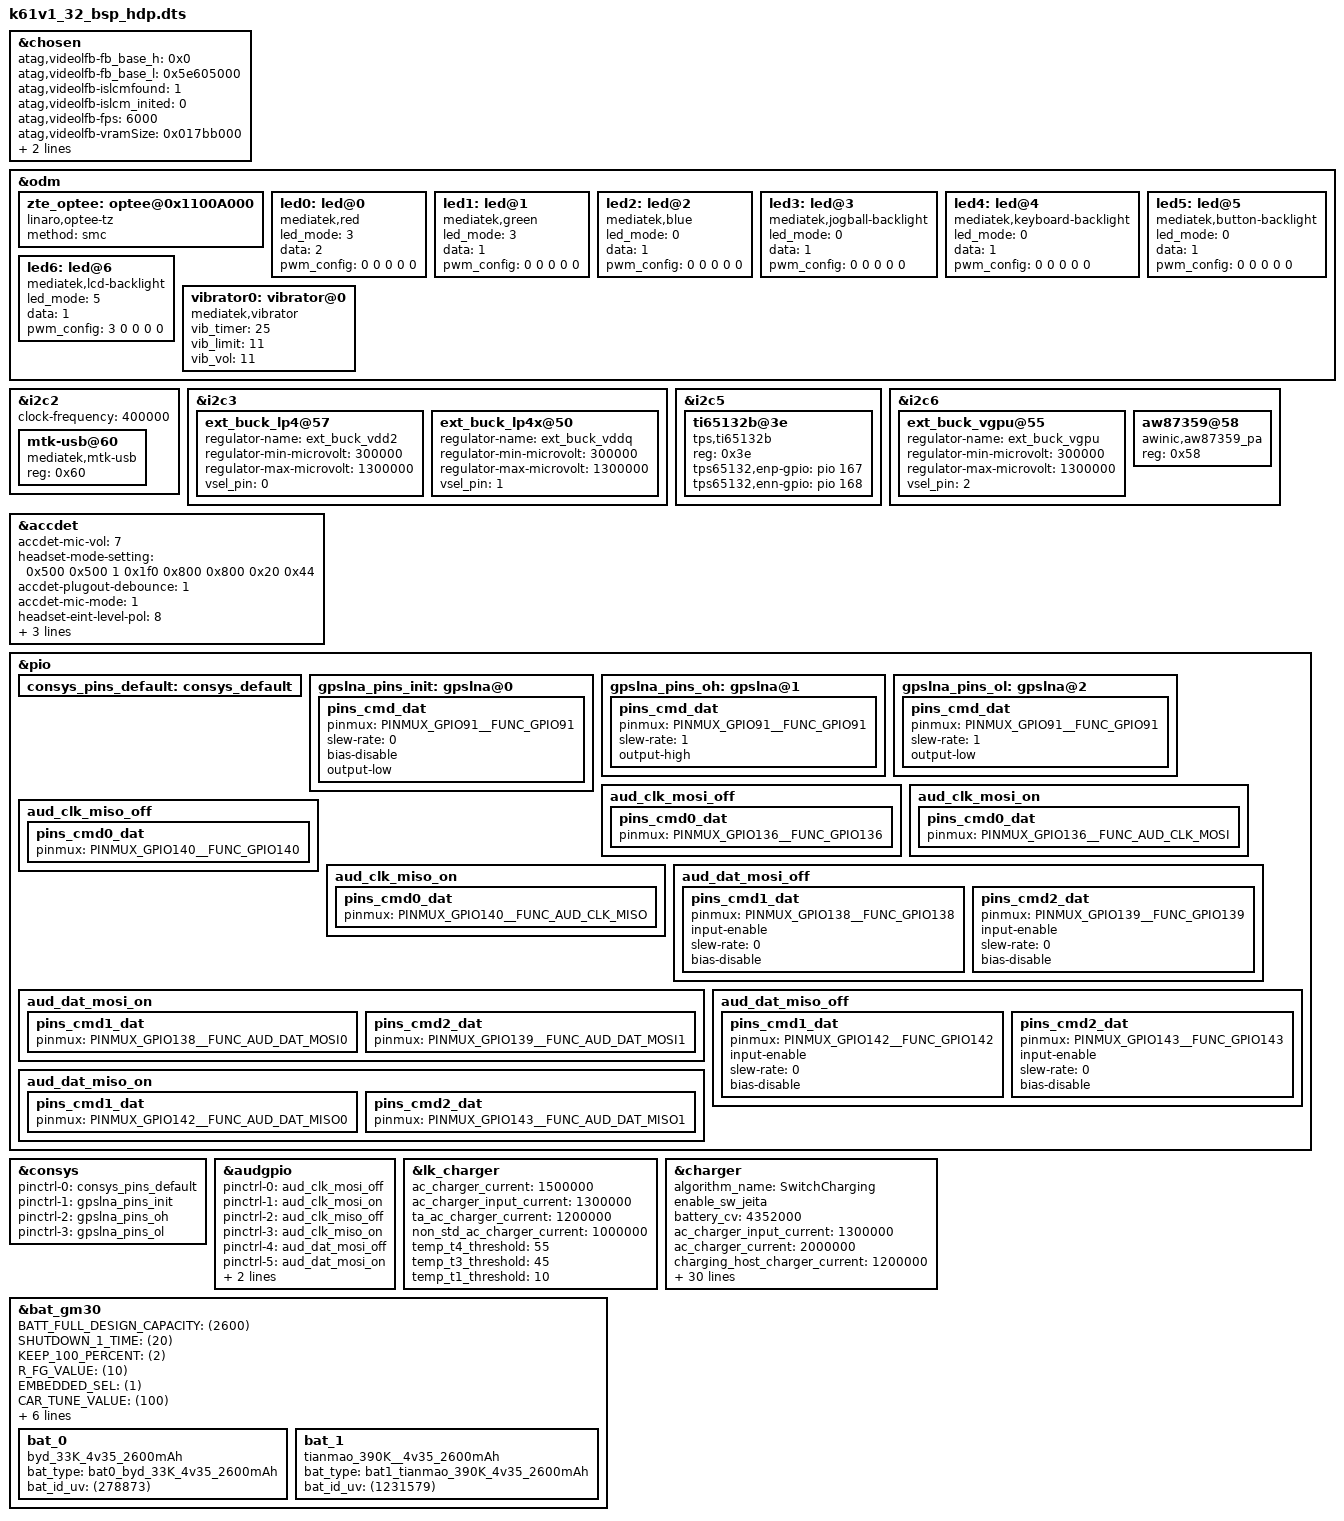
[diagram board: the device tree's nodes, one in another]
/*
 * Copyright (C) 2019 MediaTek Inc.
 *
 * This program is free software; you can redistribute it and/or modify
 * it under the terms of the GNU General Public License version 2 as
 * published by the Free Software Foundation.
 *
 * This program is distributed in the hope that it will be useful,
 * but WITHOUT ANY WARRANTY; without even the implied warranty of
 * MERCHANTABILITY or FITNESS FOR A PARTICULAR PURPOSE.
 * See http://www.gnu.org/licenses/gpl-2.0.html for more details.
 */

#include <dt-bindings/interrupt-controller/arm-gic.h>
#include <dt-bindings/interrupt-controller/irq.h>
#include <dt-bindings/pinctrl/mt6761-pinfunc.h>
#include <dt-bindings/mmc/mt6761-msdc.h>
#include <dt-bindings/clock/mt6761-clk.h>

/dts-v1/;
/plugin/;

#include "touchscreen_mango.dtsi"

/* chosen */
&chosen {

	/* fpga may has no lk, we need to specify display info here */
	/* fb buffer is reserved using this dts by memory node above */
	atag,videolfb-fb_base_h = <0x0>;
	atag,videolfb-fb_base_l = <0x5e605000>;
	atag,videolfb-islcmfound = <1>;
	/* because no lk, so lcm is not inited */
	atag,videolfb-islcm_inited = <0>;
	atag,videolfb-fps= <6000>;
	atag,videolfb-vramSize= <0x017bb000>;
	atag,videolfb-lcmname= "nt35521_hd_dsi_vdo_truly_rt5081_drv";
};

&odm {
	zte_optee: optee@0x1100A000 {
		compatible = "linaro,optee-tz";
		method = "smc";
	};
	led0:led@0 {
		compatible = "mediatek,red";
		led_mode = <3>;
		data = <2>;
		pwm_config = <0 0 0 0 0>;
	};
	led1:led@1 {
		compatible = "mediatek,green";
		led_mode = <3>;
		data = <1>;
		pwm_config = <0 0 0 0 0>;
	};
	led2:led@2 {
		compatible = "mediatek,blue";
		led_mode = <0>;
		data = <1>;
		pwm_config = <0 0 0 0 0>;
	};
	led3:led@3 {
		compatible = "mediatek,jogball-backlight";
		led_mode = <0>;
		data = <1>;
		pwm_config = <0 0 0 0 0>;
	};
	led4:led@4 {
		compatible = "mediatek,keyboard-backlight";
		led_mode = <0>;
		data = <1>;
		pwm_config = <0 0 0 0 0>;
	};
	led5:led@5 {
		compatible = "mediatek,button-backlight";
		led_mode = <0>;
		data = <1>;
		pwm_config = <0 0 0 0 0>;
	};
	led6:led@6 {
		compatible = "mediatek,lcd-backlight";
		led_mode = <5>;
		data = <1>;
		pwm_config = <3 0 0 0 0>;
	};
	vibrator0:vibrator@0 {
		compatible = "mediatek,vibrator";
		vib_timer = <25>;
		vib_limit = <11>;
		vib_vol= <11>;
	};
};

&i2c2 {
	#address-cells = <1>;
	#size-cells = <0>;
	clock-frequency = <400000>;

	mtk-usb@60 {
		compatible = "mediatek,mtk-usb";
		reg = <0x60>;
		status = "okay";
	};
};

&i2c3 {
	ext_buck_lp4@57 {
		regulator-name ="ext_buck_vdd2";
		regulator-min-microvolt = <300000>;
		regulator-max-microvolt = <1300000>;
		vsel_pin = <0>;
	};

	ext_buck_lp4x@50 {
		regulator-name ="ext_buck_vddq";
		regulator-min-microvolt = <300000>;
		regulator-max-microvolt = <1300000>;
		vsel_pin = <1>;
	};
};
&i2c5 {
       ti65132b@3e {
               compatible = "tps,ti65132b";
               reg = <0x3e>;
               tps65132,enp-gpio = <&pio 167 0x00>;
               tps65132,enn-gpio = <&pio 168 0x00>;
       };
};

&i2c6 {
	ext_buck_vgpu@55 {
		regulator-name ="ext_buck_vgpu";
		regulator-min-microvolt = <300000>;
		regulator-max-microvolt = <1300000>;
		vsel_pin = <2>;
	};
};

&accdet {
	accdet-mic-vol = <7>;
	headset-mode-setting = <0x500 0x500 1 0x1f0 0x800 0x800 0x20 0x44>;
	accdet-plugout-debounce = <1>;
	accdet-mic-mode = <1>;
	headset-eint-level-pol = <8>;
	headset-three-key-threshold = <0 80 220 400>;
	headset-three-key-threshold-CDD = <0 121 192 600>;
	headset-four-key-threshold = <0 58 121 192 400>;
	status = "okay";
};

/* CONSYS GPIO standardization */
&pio {
	consys_pins_default: consys_default {
	};
	gpslna_pins_init: gpslna@0 {
		pins_cmd_dat {
			pinmux = <PINMUX_GPIO91__FUNC_GPIO91>;
			slew-rate = <0>;
			bias-disable;
			output-low;
		};
	};
	gpslna_pins_oh: gpslna@1 {
		pins_cmd_dat {
			pinmux = <PINMUX_GPIO91__FUNC_GPIO91>;
			slew-rate = <1>;
			output-high;
		};
	};
	gpslna_pins_ol: gpslna@2 {
		pins_cmd_dat {
			pinmux = <PINMUX_GPIO91__FUNC_GPIO91>;
			slew-rate = <1>;
			output-low;
		};
	};
};
&consys {
	pinctrl-names = "default", "gps_lna_state_init",
		"gps_lna_state_oh", "gps_lna_state_ol";
	pinctrl-0 = <&consys_pins_default>;
	pinctrl-1 = <&gpslna_pins_init>;
	pinctrl-2 = <&gpslna_pins_oh>;
	pinctrl-3 = <&gpslna_pins_ol>;
	status = "okay";
};
/* CONSYS end */

/* AWINIC AW87359 Smart PA */
&i2c6 {
    aw87359@58 {
        compatible = "awinic,aw87359_pa";
        reg = <0x58>;
        status = "okay";
    };
};
/* AWINIC AW87359 Smart PA End */

/* AUDIO GPIO standardization */
&audgpio {
	pinctrl-names = "aud_clk_mosi_off",
			"aud_clk_mosi_on",
			"aud_clk_miso_off",
			"aud_clk_miso_on",
			"aud_dat_mosi_off",
			"aud_dat_mosi_on",
			"aud_dat_miso_off",
			"aud_dat_miso_on";
	pinctrl-0 = <&aud_clk_mosi_off>;
	pinctrl-1 = <&aud_clk_mosi_on>;
	pinctrl-2 = <&aud_clk_miso_off>;
	pinctrl-3 = <&aud_clk_miso_on>;
	pinctrl-4 = <&aud_dat_mosi_off>;
	pinctrl-5 = <&aud_dat_mosi_on>;
	pinctrl-6 = <&aud_dat_miso_off>;
	pinctrl-7 = <&aud_dat_miso_on>;
	status = "okay";
};

&pio {
	aud_clk_mosi_off: aud_clk_mosi_off {
		pins_cmd0_dat {
			pinmux = <PINMUX_GPIO136__FUNC_GPIO136>;
		};
	};

	aud_clk_mosi_on: aud_clk_mosi_on {
		pins_cmd0_dat {
			pinmux = <PINMUX_GPIO136__FUNC_AUD_CLK_MOSI>;
		};
	};

	aud_clk_miso_off: aud_clk_miso_off {
		pins_cmd0_dat {
			pinmux = <PINMUX_GPIO140__FUNC_GPIO140>;
		};
	};

	aud_clk_miso_on: aud_clk_miso_on {
		pins_cmd0_dat {
			pinmux = <PINMUX_GPIO140__FUNC_AUD_CLK_MISO>;
		};
	};

	aud_dat_mosi_off: aud_dat_mosi_off {
		pins_cmd1_dat {
			pinmux = <PINMUX_GPIO138__FUNC_GPIO138>;
			input-enable;
			slew-rate = <0>;
			bias-disable;
		};
		pins_cmd2_dat {
			pinmux = <PINMUX_GPIO139__FUNC_GPIO139>;
			input-enable;
			slew-rate = <0>;
			bias-disable;
		};
	};

	aud_dat_mosi_on: aud_dat_mosi_on {
		pins_cmd1_dat {
			pinmux = <PINMUX_GPIO138__FUNC_AUD_DAT_MOSI0>;
		};
		pins_cmd2_dat {
			pinmux = <PINMUX_GPIO139__FUNC_AUD_DAT_MOSI1>;
		};
	};

	aud_dat_miso_off: aud_dat_miso_off {
		pins_cmd1_dat {
			pinmux = <PINMUX_GPIO142__FUNC_GPIO142>;
			input-enable;
			slew-rate = <0>;
			bias-disable;
		};
		pins_cmd2_dat {
			pinmux = <PINMUX_GPIO143__FUNC_GPIO143>;
			input-enable;
			slew-rate = <0>;
			bias-disable;
		};
	};

	aud_dat_miso_on: aud_dat_miso_on {
		pins_cmd1_dat {
			pinmux = <PINMUX_GPIO142__FUNC_AUD_DAT_MISO0>;
		};
		pins_cmd2_dat {
			pinmux = <PINMUX_GPIO143__FUNC_AUD_DAT_MISO1>;
		};
	};
};
/* AUDIO end */


&lk_charger {
	ac_charger_current = <1500000>;
	ac_charger_input_current = <1300000>;
	ta_ac_charger_current = <1200000>;
	non_std_ac_charger_current = <1000000>;

	/* battery temperature protection */
	temp_t4_threshold = <55>;
	temp_t3_threshold = <45>;
	temp_t1_threshold = <10>;
};

&charger {
	algorithm_name = "SwitchCharging";
	enable_sw_jeita;
	battery_cv = <4352000>;
	ac_charger_input_current = <1300000>;
	ac_charger_current = <2000000>;
	charging_host_charger_current = <1200000>;
	ta_ac_charger_current = <2000000>;
	non_std_ac_charger_current = <1000000>;

	/* sw jeita */
	jeita_temp_above_t4_cv = <4100000>;
	jeita_temp_t3_to_t4_cv = <4100000>;
	jeita_temp_t2_to_t3_cv = <4352000>;
	jeita_temp_t1_to_t2_cv = <4352000>;
	jeita_temp_t0_to_t1_cv = <4352000>;
	jeita_temp_below_t0_cv = <4100000>;

	jeita_temp_above_t4_chg_current = <0>;
	jeita_temp_t3_to_t4_chg_current = <700000>;
	jeita_temp_t2_to_t3_chg_current = <2000000>;
	jeita_temp_t1_to_t2_chg_current = <600000>;
	jeita_temp_t0_to_t1_chg_current = <600000>;
	jeita_temp_below_t0_chg_current = <0>;

	temp_t4_thres = <55>;
	temp_t4_thres_minus_x_degree = <53>;
	temp_t3_thres = <45>;
	temp_t3_thres_minus_x_degree = <43>;
	temp_t2_thres = <15>;
	temp_t2_thres_plus_x_degree = <17>;
	temp_t1_thres = <1>;
	temp_t1_thres_plus_x_degree = <3>;
	temp_t0_thres = <1>;
	temp_t0_thres_plus_x_degree = <3>;
	temp_neg_10_thres = <1>;

	/* battery temperature protection */
	enable_min_charge_temp;
	min_charge_temp = <0>;
	min_charge_temp_plus_x_degree = <3>;
	max_charge_temp = <55>;
	max_charge_temp_minus_x_degree = <53>;
};

&bat_gm30 {

	BATT_FULL_DESIGN_CAPACITY = <(2600)>;
	SHUTDOWN_1_TIME = <(20)>;
	KEEP_100_PERCENT = <(2)>;
	R_FG_VALUE = <(10)>;
	EMBEDDED_SEL = <(1)>;
	CAR_TUNE_VALUE = <(100)>;

	g_FG_PSEUDO100_T0 = <(98)>;
	g_FG_PSEUDO100_T1 = <(98)>;
	g_FG_PSEUDO100_T2 = <(98)>;
	g_FG_PSEUDO100_T3 = <(98)>;
	g_FG_PSEUDO100_T4 = <(98)>;

	#include "../bat_setting/mt6761_battery_table_ext_2600mah_byd.dtsi"
	#include "../bat_setting/mt6761_battery_table_ext_2600mah_tianmao.dtsi"

	/* bat_id_pull_up_r = 180K bat_id_pull_up_volt = 1.8V */
	bat_num = <(2)>;
	bat_0 {
		compatible = "byd_33K_4v35_2600mAh";
		bat_type = "bat0_byd_33K_4v35_2600mAh";
		bat_id_uv = <(278873)>;
	};

	bat_1 {
		compatible = "tianmao_390K__4v35_2600mAh";
		bat_type = "bat1_tianmao_390K_4v35_2600mAh";
		bat_id_uv = <(1231579)>;
	};
};

#include "fingerprint_mango.dtsi"
#include <k61v1_32_bsp_hdp_mango/cust.dtsi>
#include "cust_mt6761_camera.dtsi"
/*End of this file, DO NOT ADD ANYTHING HERE*/
